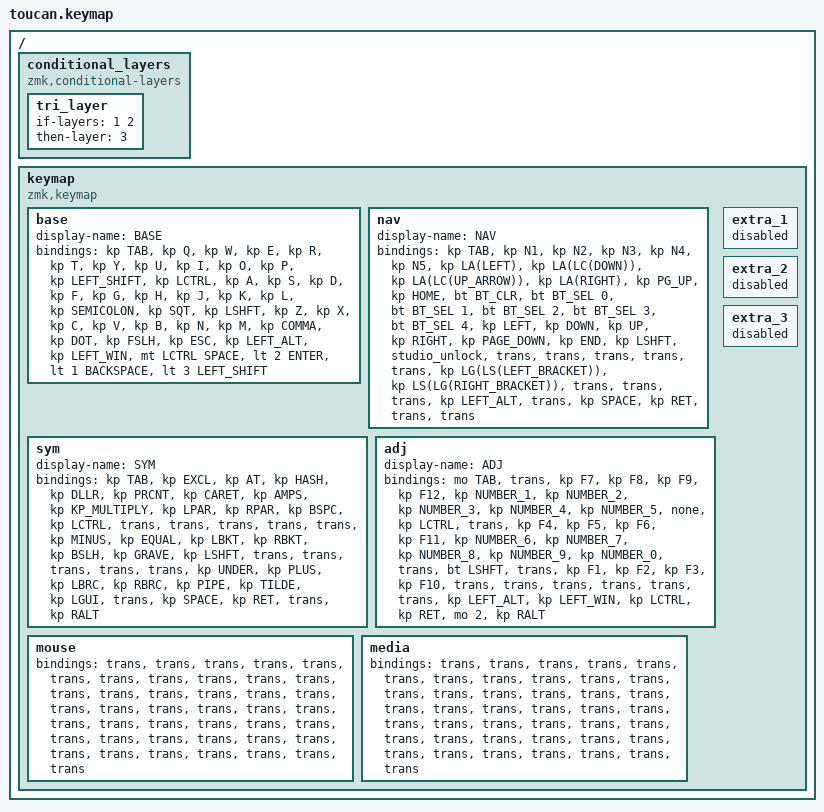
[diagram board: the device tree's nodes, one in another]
#include <behaviors.dtsi>
#include <dt-bindings/zmk/bt.h>
#include <dt-bindings/zmk/keys.h>

#define BASE 0
#define NAV  1
#define SYM  2
#define ADJ  3

/ {
    conditional_layers {
        compatible = "zmk,conditional-layers";

        tri_layer {
            if-layers = <1 2>;
            then-layer = <3>;
        };
    };

    keymap {
        compatible = "zmk,keymap";

        base {
            display-name = "BASE";
            bindings = <
&kp TAB  &kp Q  &kp W  &kp E  &kp R  &kp T  &kp Y  &kp U  &kp I  &kp O  &kp P  &kp LEFT_SHIFT  &kp LCTRL  &kp A  &kp S  &kp D  &kp F  &kp G  &kp H  &kp J  &kp K  &kp L  &kp SEMICOLON  &kp SQT  &kp LSHFT  &kp Z  &kp X  &kp C  &kp V  &kp B  &kp N  &kp M  &kp COMMA  &kp DOT  &kp FSLH  &kp ESC  &kp LEFT_ALT  &kp LEFT_WIN  &mt LCTRL SPACE  &lt 2 ENTER  &lt 1 BACKSPACE  &lt 3 LEFT_SHIFT
            >;
        };

        nav {
            display-name = "NAV";
            bindings = <
&kp TAB  &kp N1  &kp N2  &kp N3  &kp N4  &kp N5  &kp LA(LEFT)  &kp LA(LC(DOWN))  &kp LA(LC(UP_ARROW))  &kp LA(RIGHT)  &kp PG_UP  &kp HOME  &bt BT_CLR  &bt BT_SEL 0  &bt BT_SEL 1  &bt BT_SEL 2  &bt BT_SEL 3  &bt BT_SEL 4  &kp LEFT  &kp DOWN  &kp UP  &kp RIGHT  &kp PAGE_DOWN  &kp END  &kp LSHFT  &studio_unlock  &trans  &trans  &trans  &trans  &trans  &kp LG(LS(LEFT_BRACKET))  &kp LS(LG(RIGHT_BRACKET))  &trans  &trans  &trans  &kp LEFT_ALT  &trans  &kp SPACE  &kp RET  &trans  &trans
            >;
        };

        sym {
            display-name = "SYM";
            bindings = <
&kp TAB  &kp EXCL  &kp AT  &kp HASH  &kp DLLR  &kp PRCNT  &kp CARET  &kp AMPS  &kp KP_MULTIPLY  &kp LPAR  &kp RPAR  &kp BSPC  &kp LCTRL  &trans  &trans  &trans  &trans  &trans  &kp MINUS  &kp EQUAL  &kp LBKT  &kp RBKT  &kp BSLH  &kp GRAVE  &kp LSHFT  &trans  &trans  &trans  &trans  &trans  &kp UNDER  &kp PLUS  &kp LBRC  &kp RBRC  &kp PIPE  &kp TILDE  &kp LGUI  &trans  &kp SPACE  &kp RET  &trans  &kp RALT
            >;
        };

        adj {
            display-name = "ADJ";
            bindings = <
&mo TAB  &trans  &kp F7  &kp F8  &kp F9  &kp F12  &kp NUMBER_1  &kp NUMBER_2  &kp NUMBER_3  &kp NUMBER_4  &kp NUMBER_5  &none  &kp LCTRL  &trans  &kp F4  &kp F5  &kp F6  &kp F11  &kp NUMBER_6  &kp NUMBER_7  &kp NUMBER_8  &kp NUMBER_9  &kp NUMBER_0  &trans  &bt LSHFT  &trans  &kp F1  &kp F2  &kp F3  &kp F10  &trans  &trans  &trans  &trans  &trans  &trans  &kp LEFT_ALT  &kp LEFT_WIN  &kp LCTRL  &kp RET  &mo 2  &kp RALT
            >;
        };

        extra_1 { status = "reserved"; };

        extra_2 { status = "reserved"; };

        extra_3 { status = "reserved"; };

        mouse {
            bindings = <
&trans  &trans  &trans  &trans  &trans  &trans  &trans  &trans  &trans  &trans  &trans  &trans  &trans  &trans  &trans  &trans  &trans  &trans  &trans  &trans  &trans  &trans  &trans  &trans  &trans  &trans  &trans  &trans  &trans  &trans  &trans  &trans  &trans  &trans  &trans  &trans  &trans  &trans  &trans  &trans  &trans  &trans
            >;
        };

        media {
            bindings = <
&trans  &trans  &trans  &trans  &trans  &trans  &trans  &trans  &trans  &trans  &trans  &trans  &trans  &trans  &trans  &trans  &trans  &trans  &trans  &trans  &trans  &trans  &trans  &trans  &trans  &trans  &trans  &trans  &trans  &trans  &trans  &trans  &trans  &trans  &trans  &trans  &trans  &trans  &trans  &trans  &trans  &trans
            >;
        };
    };
};
